# iCEBESOC register map
Vendor: litex
Litex SoC 2021-10-13 15:22:10
Registers are 32-bit, read-write, reset 0x0 unless marked. A register's access mark holds for its fields unless they carry their own. Offsets are from the block's base; lines under a group give offsets from that group; [hi:lo] are bit positions; {n}, {i} and the like mark numbered series; 'fields as' and 'values as' point back to an identical list; <NAME> marks a mode.

## Memory map
0xF0000000 LEDS size 0x4
0xF0000800 CTRL size 0xC
0xF0001000 SPIFLASH_CORE size 0x4
0xF0001800 SPIFLASH_PHY size 0x4
0xF0002000 TIMER0 size 0x20
0xF0002800 UART size 0x20

## Interrupts
0 uart (UART)
1 timer0 (TIMER0)

## Further device data
memoryRegions:
  SRAM baseAddress=0x10000000 size=0x00020000
  SPIFLASH baseAddress=0x20000000 size=0x01000000
  ROM baseAddress=0x20040000 size=0x00800000
  CSR baseAddress=0xF0000000 size=0x00010000
constants:
  CONFIG_CLOCK_FREQUENCY value=21000000
  CONFIG_CPU_HAS_INTERRUPT value=None
  CONFIG_CPU_RESET_ADDR value=537133056
  CONFIG_CPU_HAS_ICACHE value=None
  CONFIG_CPU_TYPE_VEXRISCV value=None
  CONFIG_CPU_VARIANT_LITE value=None
  CONFIG_CPU_HUMAN_NAME value=VexRiscv_Lite
  CONFIG_CPU_NOP value=nop
  SPIFLASH_PHY_FREQUENCY value=21000000
  SPIFLASH_MODULE_NAME value=W25Q128JV
  SPIFLASH_MODULE_TOTAL_SIZE value=16777216
  SPIFLASH_MODULE_PAGE_SIZE value=256
  SPIFLASH_MODULE_QUAD_CAPABLE value=None
  CONFIG_CSR_DATA_WIDTH value=32
  CONFIG_CSR_ALIGNMENT value=32
  CONFIG_BUS_STANDARD value=WISHBONE
  CONFIG_BUS_DATA_WIDTH value=32
  CONFIG_BUS_ADDRESS_WIDTH value=32
  TIMER0_INTERRUPT value=1
  UART_INTERRUPT value=0

## LEDS
Base 0xF0000000
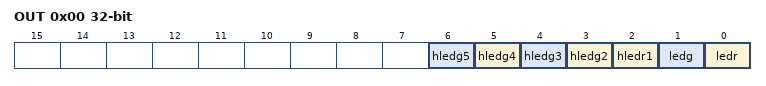
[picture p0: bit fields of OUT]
0x00 OUT
  [n+1] hledg{n} (n=2..5) — Green LED #{n} on the iCEBreaker head.
  [2] hledr1 — The center Red LED #1 on the iCEBreaker head.
  [1] ledg — The Green LED on the main iCEBreaker board.
  [0] ledr — The Red LED on the main iCEBreaker board.

## CTRL
Base 0xF0000800
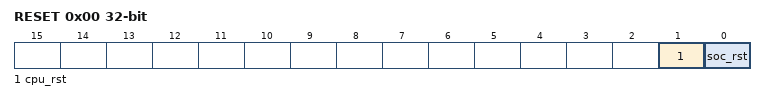
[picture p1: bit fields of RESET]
0x00 RESET
  [1] cpu_rst — Write `1` to this register to reset the CPU(s) of the SoC (Hold Reset)
  [0] soc_rst — Write `1` to this register to reset the full SoC (Pulse Reset)
0x04 SCRATCH reset 0x12345678 — Use this register as a scratch space to verify that software read/write accesses to the Wishbone/CSR bus are working correctly. The initial reset value of 0x1234578 can be used to verify endianness.
0x08 BUS_ERRORS — Total number of Wishbone bus errors (timeouts) since start.

## SPIFLASH_CORE
Base 0xF0001000
0x00 MMAP_DUMMY_BITS reset 0x8
  [7:0] mmap_dummy_bits

## SPIFLASH_PHY
Base 0xF0001800
0x00 CLK_DIVISOR reset 0x1
  [7:0] clk_divisor

## TIMER0
Base 0xF0002000
0x00 LOAD — Load value when Timer is (re-)enabled. In One-Shot mode, the value written to this register specifies the Timer's duration in clock cycles.
0x04 RELOAD — Reload value when Timer reaches ``0``. In Periodic mode, the value written to this register specify the Timer's period in clock cycles.
0x08 EN — Enable flag of the Timer. Set this flag to ``1`` to enable/start the Timer. Set to ``0`` to disable the Timer.
  [0] en
0x0C UPDATE_VALUE — Update trigger for the current countdown value. A write to this register latches the current countdown value to ``value`` register.
  [0] update_value
0x10 VALUE — Latched countdown value. This value is updated by writing to ``update_value``.
0x14 EV_STATUS — This register contains the current raw level of the zero event trigger. Writes to this register have no effect.
  [0] zero — Level of the ``zero`` event
0x18 EV_PENDING — When a zero event occurs, the corresponding bit will be set in this register. To clear the Event, set the corresponding bit in this register.
  [0] zero — `1` if a `zero` event occurred. This Event is triggered on a **falling** edge.
0x1C EV_ENABLE — This register enables the corresponding zero events. Write a ``0`` to this register to disable individual events.
  [0] zero — Write a ``1`` to enable the ``zero`` Event

## UART
Base 0xF0002800
0x00 RXTX
  [7:0] rxtx
0x04 TXFULL — TX FIFO Full.
  [0] txfull
0x08 RXEMPTY — RX FIFO Empty.
  [0] rxempty
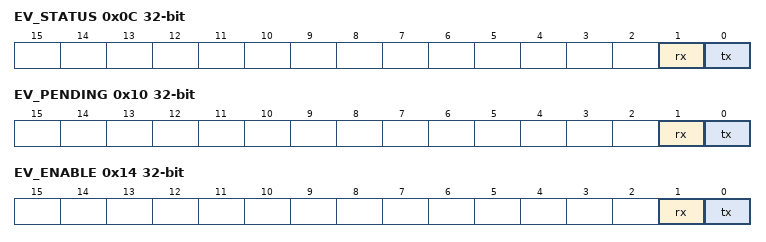
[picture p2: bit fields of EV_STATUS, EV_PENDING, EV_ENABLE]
0x0C EV_STATUS — This register contains the current raw level of the rx event trigger. Writes to this register have no effect.
  [1] rx — Level of the ``rx`` event
  [0] tx — Level of the ``tx`` event
0x10 EV_PENDING — When a rx event occurs, the corresponding bit will be set in this register. To clear the Event, set the corresponding bit in this register.
  [1] rx — `1` if a `rx` event occurred. This Event is triggered on a **falling** edge.
  [0] tx — `1` if a `tx` event occurred. This Event is triggered on a **falling** edge.
0x14 EV_ENABLE — This register enables the corresponding rx events. Write a ``0`` to this register to disable individual events.
  [1] rx — Write a ``1`` to enable the ``rx`` Event
  [0] tx — Write a ``1`` to enable the ``tx`` Event
0x18 TXEMPTY — TX FIFO Empty.
  [0] txempty
0x1C RXFULL — RX FIFO Full.
  [0] rxfull
